# MSPM0G511X register map
Vendor: Texas Instruments; File version: Revised: 2025-07-22 15:38:34
CPU: CM0 r0p1, little endian, MPU, no FPU, 3 interrupt priority bits
Registers are 32-bit, read-write, reset 0x0 unless marked. A register's access mark holds for its fields unless they carry their own. Offsets are from the block's base; [hi:lo] are bit positions; lines under a group give offsets from that group; {n}, {i} and the like mark numbered series.

## KEYSTORECTL — PERIPHERALREGION
Base 0x400AC000
0x1100 KEYSTORECTL_CFG reset 0x1 — Keystore configuration
  [3:0] NK256 — Number of 256 bit keys to be held in the key-store. Can not exceed the total number of slots present in the hardware / 2. For eg: if SYS_N_SLOTS = 4, then atmost 2 256-bit keys can be held in the key-store. Incorrect setting of this field will be reported via STATUS register
    0=ZERO (No 256-bit keys); 1=ONE (One 256-bit key); 2=TWO (Two 256-bit keys); 3=THREE (Three 256-bit keys); 4=FOUR (Four 256-bit keys)
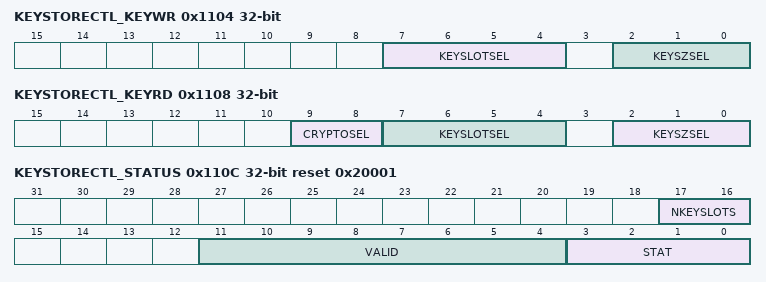
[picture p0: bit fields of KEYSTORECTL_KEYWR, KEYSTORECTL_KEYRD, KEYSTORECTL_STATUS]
0x1104 KEYSTORECTL_KEYWR — Key write configuration
  [7:4] KEYSLOTSEL — Select the key slot to write the key into. NOTE: SW needs to ensure that it is writing to the correct slots. The slot numbering is from 0 through SYS_N_SLOTS-1. Each slot is a 128-bit slot. Therefore, when writing a 256-bit key, two slots will need to budgeted. The selected slot for the 256-bit key needs to be an even numbered slot (eg: 0 or 2). Also all the 256-bit keys need to be stored in lower numbered slots and 128-bit keys stored in higher numbered slots.
    {v}=SLOT{v} (v=0..7)
  [2:0] KEYSZSEL — Key size selection. Selection of 128 or 256 bit keys
    0=K256 (256 bit key); 1=K128 (128 bit key)
0x1108 KEYSTORECTL_KEYRD — Key read configuration
  [9:8] CRYPTOSEL — Crypto engine selector
    0=AES (Transfer key to AES)
  [7:4] KEYSLOTSEL — Select the key slot to read the key from. NOTE: SW needs to ensure that it is reading from the correct slots. The slot numbering is from 0 through SYS_N_SLOTS-1. Each slot is a 128-bit slot. Therefore, when reading a 256-bit key, two adjacent slots will be read. For a 256-bit key, an even numbered slot index must be specified.
  [2:0] KEYSZSEL — Key size selection. Selection of 128 or 256 bit keys
    0=K256 (256 bit key); 1=K128 (128 bit key)
0x110C KEYSTORECTL_STATUS ro reset 0x20001 — Status
  [17:16] NKEYSLOTS — Size of keystorage: Number of 128-bit key slots
    0=TWO (Two slots); 1=THREE (Three slots); 2=FOUR (Four slots)
  [11:4] VALID — Bitvector of valid bits to indicate which slots have been configured
  [3:0] STAT — Status information
    0=VALID (Valid configuration); 1=NO_CFG (Key-store has not been configured. NK256 has not been set.); 2=INVALID_NK256 (Invalid value for NK256 field in CFG.); 3=BUSY_RECEIVE (Busy receiving a key deposit); 4=BUSY_TRANSMIT (Busy transmitting a key to a crypto engine); 5=INVALID_KEYSLOTSELW (Invalid keyslot selection for writing); 6=INVALID_KEYSLOTSELR (Invalid keyslot selection for reading)
0x1110 KEYSTORECTL_KEYIN wo — Input key
0x1114 KEYSTORECTL_KEYLOCK — Keylock
  [7:0] LOCKBIT — Bitvector of lock bits to lock certain slots from being used by application.

## CRCP0 — PERIPHERALREGION
Base 0x40440000
{0x800+0x18*i} CRCP0_GPRCM[{i}] (i=0..0) group
  0x00 CRCP0_PWREN — Power enable
    [0] ENABLE — Enable the power
      0=DISABLE (Disable Power); 1=ENABLE (Enable Power)
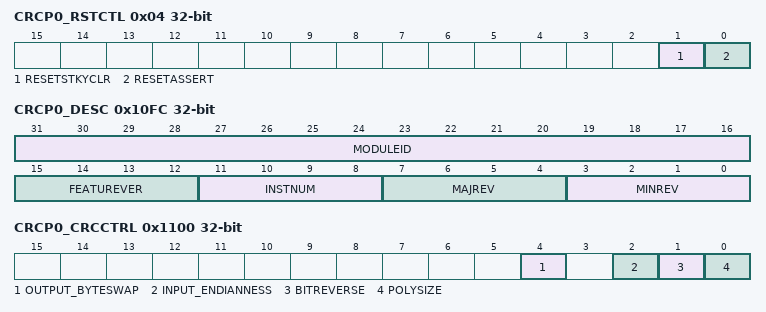
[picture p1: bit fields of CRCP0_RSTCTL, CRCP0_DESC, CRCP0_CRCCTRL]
  0x04 CRCP0_RSTCTL wo — Reset Control
    [1] RESETSTKYCLR — Clear the RESETSTKY bit in the STAT register
      0=NOP (Writing 0 has no effect); 1=CLR (Clear reset sticky bit)
    [0] RESETASSERT — Assert reset to the peripheral
      0=NOP (Writing 0 has no effect); 1=ASSERT (Assert reset)
  0x14 CRCP0_STAT ro — Status Register
    [16] RESETSTKY — This bit indicates, if the peripheral was reset, since this bit was cleared by RESETSTKYCLR in the RSTCTL register
      0=NORES (The peripheral has not been reset since this bit was last cleared by RESETSTKYCLR in the RSTCTL register); 1=RESET (The peripheral was reset since the last bit clear)
0x10FC CRCP0_DESC ro — Module Description
  [31:16] MODULEID — Module identification contains a unique peripheral identification number. The assignments are maintained in a central database for all of the platform modules to ensure uniqueness.
  [15:12] FEATUREVER — Feature Set for the module *instance*
  [11:8] INSTNUM — Instance Number within the device. This will be a parameter to the RTL for modules that can have multiple instances
  [7:4] MAJREV — Major rev of the IP
  [3:0] MINREV — Minor rev of the IP
0x1100 CRCP0_CRCCTRL (reset mask 0x7) — CRC Control Register
  [4] OUTPUT_BYTESWAP — CRC Output Byteswap Enable. This bit controls whether the output is byte-swapped upon a read of the CRCOUT register. If CRCOUT is accessed as a half-word, and the OUTPUT_BYTESWAP is set to to 1, then the two bytes in the 16-bit access are swapped and returned. B1 is returned as B0 B0 is returned as B1 If CRCOUT is accessed as a word, and the OUTPUT_BYTESWAP is set to 1, then the four bytes in the 32-bit read are swapped. B3 is returned as B0 B2 is returned as B1 B1 is returned as B2 B0 is returned as B3 Note that if the CRC POLYSIZE is 16-bit and a 32-bit read of CRCOUT is performed with OUTPUT_BYTESWAP enabled, then the output is: MSB LSB 0x0 0x0 B0 B1 If the CRC POLYSIZE is 16-bit and a 32-bit read of CRCOUT is performed with OUTPUT_BYTESWAP disabled, then the output is: MSB LSB 0x0 0x0 B1 B0
    0=DISABLE (Output byteswapping is disabled); 1=ENABLE (Output byteswapping is enabled.)
  [2] INPUT_ENDIANNESS — CRC Endian. This bit indicates the byte order within a word or half word of input data.
    0=LITTLE_ENDIAN (LSB is lowest memory address and first to be processed.); 1=BIG_ENDIAN (LSB is highest memory address and last to be processed.)
  [1] BITREVERSE — CRC Bit Input and output Reverse. This bit indictes that the bit order of each input byte used for the CRC calculation is reversed before it is passed to the generator, and that the bit order of the calculated CRC is be reversed when read from CRC_RESULT.
    0=NOT_REVERSED (Bit order is not reversed.); 1=REVERSED (Bit order is reversed.)
  [0] POLYSIZE — This bit indicates which CRC calculation is performed by the generator.
    0=CRC32 (CRC-32 ISO-3309 calulation is performed); 1=CRC16 (CRC-16 CCITT is performed)
0x1104 CRCP0_CRCSEED wo — CRC Seed Register
  [31:0] SEED — Seed Data
0x1108 CRCP0_CRCIN wo — CRC Input Data Register
  [31:0] DATA — Input Data
0x110C CRCP0_CRCOUT ro — CRC Output Result Register
  [31:0] RESULT
0x1110 CRCP0_CRCPOLY — CRC Polynomial configuration register
{0x1800+4i} CRCP0_CRCIN_IDX[{i}] (i=0..511) wo — CRC Input Data Array Register
  [31:0] DATA — Input Data

## Notices in the file
Copyright (C) 2025 Texas Instruments Incorporated - http://www.ti.com
Redistribution and use in source and binary forms, with or without
modification, are permitted provided that the following conditions
are met:
Redistributions of source code must retain the above copyright
notice, this list of conditions and the following disclaimer.
Redistributions in binary form must reproduce the above copyright
notice, this list of conditions and the following disclaimer in the
documentation and/or other materials provided with the
distribution.
Neither the name of Texas Instruments Incorporated nor the names of
its contributors may be used to endorse or promote products derived
from this software without specific prior written permission.
THIS SOFTWARE IS PROVIDED BY THE COPYRIGHT HOLDERS AND CONTRIBUTORS
"AS IS" AND ANY EXPRESS OR IMPLIED WARRANTIES, INCLUDING, BUT NOT
LIMITED TO, THE IMPLIED WARRANTIES OF MERCHANTABILITY AND FITNESS FOR
A PARTICULAR PURPOSE ARE DISCLAIMED. IN NO EVENT SHALL THE COPYRIGHT
OWNER OR CONTRIBUTORS BE LIABLE FOR ANY DIRECT, INDIRECT, INCIDENTAL,
SPECIAL, EXEMPLARY, OR CONSEQUENTIAL DAMAGES (INCLUDING, BUT NOT
LIMITED TO, PROCUREMENT OF SUBSTITUTE GOODS OR SERVICES; LOSS OF USE,
DATA, OR PROFITS; OR BUSINESS INTERRUPTION) HOWEVER CAUSED AND ON ANY
THEORY OF LIABILITY, WHETHER IN CONTRACT, STRICT LIABILITY, OR TORT
(INCLUDING NEGLIGENCE OR OTHERWISE) ARISING IN ANY WAY OUT OF THE USE
OF THIS SOFTWARE, EVEN IF ADVISED OF THE POSSIBILITY OF SUCH DAMAGE.
